VERSION ""

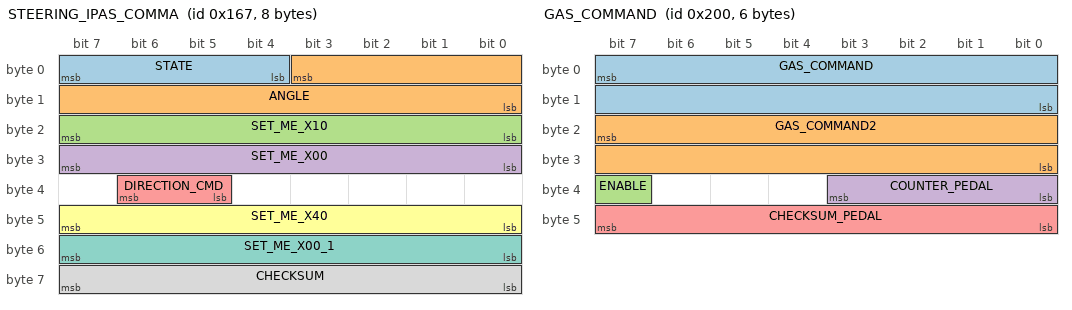
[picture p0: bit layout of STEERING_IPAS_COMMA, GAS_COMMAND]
BO_ 359 STEERING_IPAS_COMMA: 8 IPAS
 SG_ STATE : 7|4@0+ (1,0) [0|15] "" XXX
 SG_ ANGLE : 3|12@0- (1.5,0) [-510|510] "deg" XXX
 SG_ SET_ME_X10 : 23|8@0+ (1,0) [0|255] "" XXX
 SG_ SET_ME_X00 : 31|8@0+ (1,0) [0|255] "" XXX
 SG_ DIRECTION_CMD : 38|2@0+ (1,0) [0|3] "" XXX
 SG_ SET_ME_X40 : 47|8@0+ (1,0) [0|255] "" XXX
 SG_ SET_ME_X00_1 : 55|8@0+ (1,0) [0|255] "" XXX
 SG_ CHECKSUM : 63|8@0+ (1,0) [0|255] "" XXX

BO_ 512 GAS_COMMAND: 6 EON
 SG_ GAS_COMMAND : 7|16@0+ (0.159375,-75.555) [0|1] "" INTERCEPTOR
 SG_ GAS_COMMAND2 : 23|16@0+ (0.159375,-151.111) [0|1] "" INTERCEPTOR
 SG_ ENABLE : 39|1@0+ (1,0) [0|1] "" INTERCEPTOR
 SG_ COUNTER_PEDAL : 35|4@0+ (1,0) [0|15] "" INTERCEPTOR
 SG_ CHECKSUM_PEDAL : 47|8@0+ (1,0) [0|255] "" INTERCEPTOR

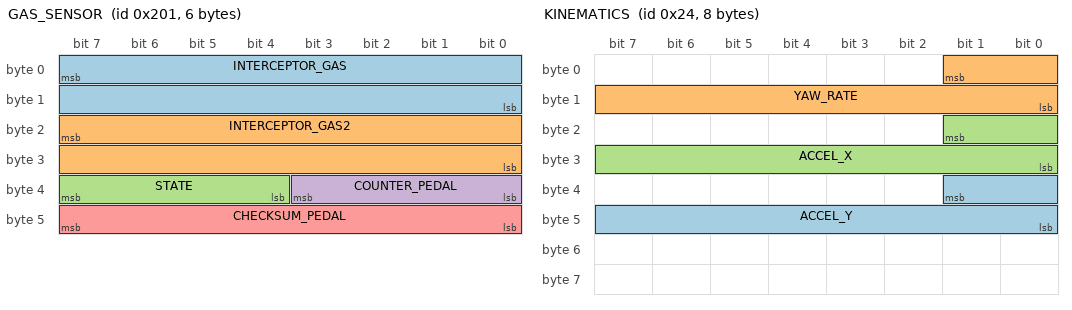
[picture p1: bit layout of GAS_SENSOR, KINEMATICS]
BO_ 513 GAS_SENSOR: 6 INTERCEPTOR
 SG_ INTERCEPTOR_GAS : 7|16@0+ (1,0) [0|1] "" EON
 SG_ INTERCEPTOR_GAS2 : 23|16@0+ (1,0) [0|1] "" EON
 SG_ STATE : 39|4@0+ (1,0) [0|15] "" EON
 SG_ COUNTER_PEDAL : 35|4@0+ (1,0) [0|15] "" EON
 SG_ CHECKSUM_PEDAL : 47|8@0+ (1,0) [0|255] "" EON

BO_ 35 SECONDARY_STEER_ANGLE: 8 XXX
 SG_ ZORRO_STEER : 7|24@0- (0.004901594652,0) [-500|500] "" XXX

BO_ 767 SDSU: 8 XXX
 SG_ FD_BUTTON : 7|1@0+ (1,0) [0|1] "" XXX

BO_ 36 KINEMATICS: 8 XXX
 SG_ ACCEL_Y : 33|10@0+ (0.03589,-18.375) [0|65535] "m/s^2" XXX
 SG_ YAW_RATE : 1|10@0+ (0.244,-125) [0|65535] "deg/s" XXX
 SG_ ACCEL_X : 17|10@0+ (0.03589,-18.375) [0|65535] "m/s^2" XXX

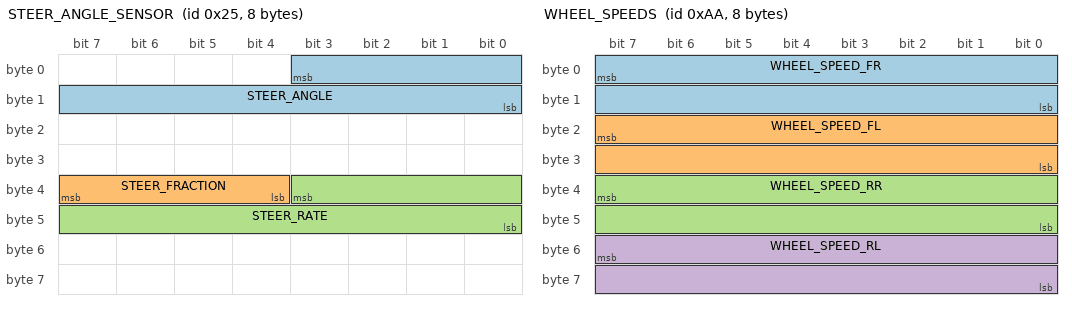
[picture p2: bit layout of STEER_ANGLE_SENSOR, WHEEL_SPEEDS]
BO_ 37 STEER_ANGLE_SENSOR: 8 XXX
 SG_ STEER_ANGLE : 3|12@0- (1.5,0) [-500|500] "deg" XXX
 SG_ STEER_FRACTION : 39|4@0- (0.1,0) [-0.7|0.7] "deg" XXX
 SG_ STEER_RATE : 35|12@0- (1,0) [-2000|2000] "deg/s" XXX

BO_ 166 BRAKE: 8 XXX
 SG_ BRAKE_AMOUNT : 7|8@0+ (1,0) [0|255] "" XXX
 SG_ BRAKE_PEDAL : 23|8@0+ (1,0) [0|255] "" XXX

BO_ 170 WHEEL_SPEEDS: 8 XXX
 SG_ WHEEL_SPEED_FR : 7|16@0+ (0.01,-67.67) [0|250] "km/h" XXX
 SG_ WHEEL_SPEED_FL : 23|16@0+ (0.01,-67.67) [0|250] "km/h" XXX
 SG_ WHEEL_SPEED_RR : 39|16@0+ (0.01,-67.67) [0|250] "km/h" XXX
 SG_ WHEEL_SPEED_RL : 55|16@0+ (0.01,-67.67) [0|250] "km/h" XXX

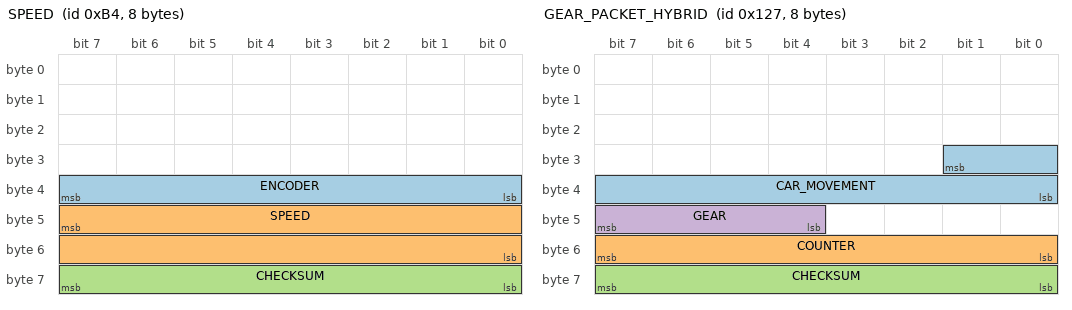
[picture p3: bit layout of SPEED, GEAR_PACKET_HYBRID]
BO_ 180 SPEED: 8 XXX
 SG_ ENCODER : 39|8@0+ (1,0) [0|255] "" XXX
 SG_ SPEED : 47|16@0+ (0.01,0) [0|250] "km/h" XXX
 SG_ CHECKSUM : 63|8@0+ (1,0) [0|255] "" XXX

BO_ 295 GEAR_PACKET_HYBRID: 8 XXX
 SG_ CAR_MOVEMENT : 25|10@0- (1,0) [0|255] "" XXX
 SG_ COUNTER : 55|8@0+ (1,0) [0|255] "" XXX
 SG_ CHECKSUM : 63|8@0+ (1,0) [0|255] "" XXX
 SG_ GEAR : 47|4@0+ (1,0) [0|15] "" XXX

BO_ 353 DSU_SPEED: 7 XXX
 SG_ FORWARD_SPEED : 15|16@0- (0.00390625,-30) [0|255] "km/h" XXX

BO_ 452 ENGINE_RPM: 8 CGW
 SG_ RPM : 7|16@0- (0.78125,0) [0|0] "rpm" SCS

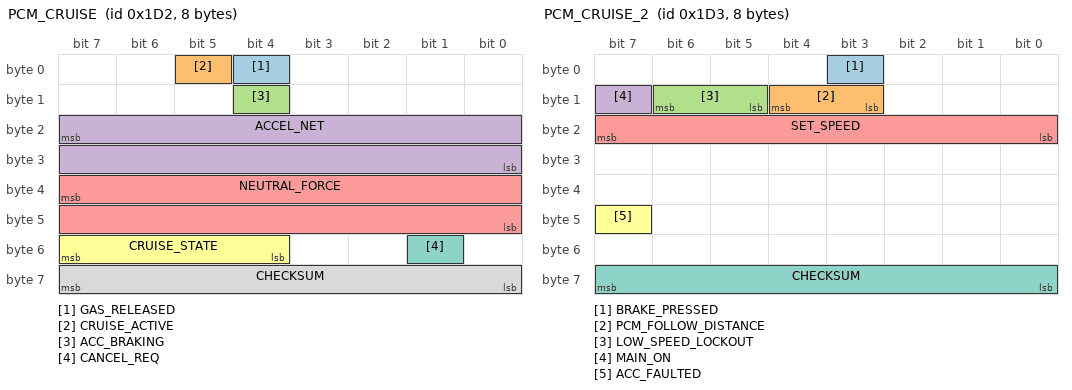
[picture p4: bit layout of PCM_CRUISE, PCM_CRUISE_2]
BO_ 466 PCM_CRUISE: 8 XXX
 SG_ GAS_RELEASED : 4|1@0+ (1,0) [0|1] "" XXX
 SG_ CRUISE_ACTIVE : 5|1@0+ (1,0) [0|1] "" XXX
 SG_ ACC_BRAKING : 12|1@0+ (1,0) [0|1] "" XXX
 SG_ ACCEL_NET : 23|16@0- (0.0009765625,0) [-20|20] "m/s^2" XXX
 SG_ NEUTRAL_FORCE : 39|16@0- (2,0) [-65536|65534] "N" XXX
 SG_ CRUISE_STATE : 55|4@0+ (1,0) [0|15] "" XXX
 SG_ CANCEL_REQ : 49|1@1+ (1,0) [0|1] "" XXX
 SG_ CHECKSUM : 63|8@0+ (1,0) [0|255] "" XXX

BO_ 467 PCM_CRUISE_2: 8 XXX
 SG_ BRAKE_PRESSED : 3|1@0+ (1,0) [0|1] "" XXX
 SG_ PCM_FOLLOW_DISTANCE : 12|2@0+ (1,0) [0|3] "" XXX
 SG_ LOW_SPEED_LOCKOUT : 14|2@0+ (1,0) [0|3] "" XXX
 SG_ MAIN_ON : 15|1@0+ (1,0) [0|1] "" XXX
 SG_ SET_SPEED : 23|8@0+ (1,0) [0|255] "km/h" XXX
 SG_ ACC_FAULTED : 47|1@0+ (1,0) [0|1] "" XXX
 SG_ CHECKSUM : 63|8@0+ (1,0) [0|255] "" XXX

BO_ 552 ACCELEROMETER: 8 XXX
 SG_ ACCEL_Z : 22|15@0- (1,0) [0|32767] "m/s^2" XXX
 SG_ ACCEL_X : 6|15@0- (0.001,0) [-20|20] "m/s^2" XXX

BO_ 560 BRAKE_2: 7 XXX
 SG_ BRAKE_PRESSED : 26|1@0+ (1,0) [0|1] "" XXX

BO_ 581 GAS_PEDAL_HYBRID: 8 XXX
 SG_ GAS_PEDAL : 23|8@0+ (0.005,0) [0|1] "" XXX

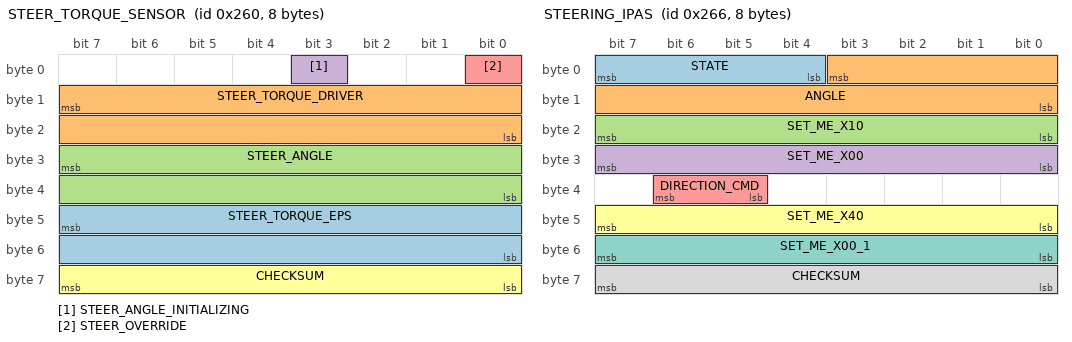
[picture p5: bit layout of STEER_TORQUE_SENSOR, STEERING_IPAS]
BO_ 608 STEER_TORQUE_SENSOR: 8 XXX
 SG_ STEER_TORQUE_EPS : 47|16@0- (1,0) [-32768|32767] "" XXX
 SG_ STEER_TORQUE_DRIVER : 15|16@0- (1,0) [-32768|32767] "" XXX
 SG_ STEER_ANGLE : 31|16@0- (0.0573,0) [-500|500] "" XXX
 SG_ STEER_ANGLE_INITIALIZING : 3|1@0+ (1,0) [0|1] "" XXX
 SG_ STEER_OVERRIDE : 0|1@0+ (1,0) [0|1] "" XXX
 SG_ CHECKSUM : 63|8@0+ (1,0) [0|255] "" XXX

BO_ 614 STEERING_IPAS: 8 IPAS
 SG_ STATE : 7|4@0+ (1,0) [0|15] "" XXX
 SG_ ANGLE : 3|12@0- (1.5,0) [-510|510] "deg" XXX
 SG_ SET_ME_X10 : 23|8@0+ (1,0) [0|255] "" XXX
 SG_ SET_ME_X00 : 31|8@0+ (1,0) [0|255] "" XXX
 SG_ DIRECTION_CMD : 38|2@0+ (1,0) [0|3] "" XXX
 SG_ SET_ME_X40 : 47|8@0+ (1,0) [0|255] "" XXX
 SG_ SET_ME_X00_1 : 55|8@0+ (1,0) [0|255] "" XXX
 SG_ CHECKSUM : 63|8@0+ (1,0) [0|255] "" XXX

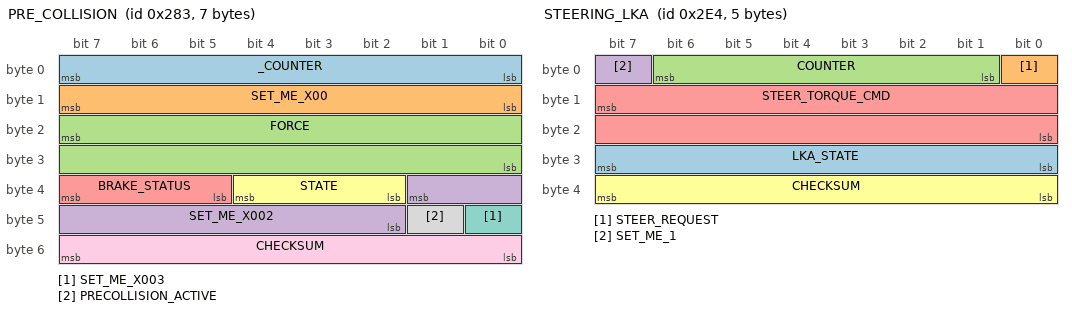
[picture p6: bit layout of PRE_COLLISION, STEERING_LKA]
BO_ 643 PRE_COLLISION: 7 DSU
 SG_ _COUNTER : 7|8@0+ (1,0) [0|255] "" XXX
 SG_ SET_ME_X00 : 15|8@0+ (1,0) [0|255] "" XXX
 SG_ FORCE : 23|16@0- (2,0) [0|255] "N" XXX
 SG_ SET_ME_X002 : 33|8@0+ (1,0) [0|3] "" XXX
 SG_ BRAKE_STATUS : 39|3@0+ (1,0) [0|255] "" XXX
 SG_ STATE : 36|3@0+ (1,0) [0|255] "" XXX
 SG_ SET_ME_X003 : 40|1@0+ (1,0) [0|1] "" XXX
 SG_ PRECOLLISION_ACTIVE : 41|1@0+ (1,0) [0|255] "" XXX
 SG_ CHECKSUM : 55|8@0+ (1,0) [0|255] "" XXX

BO_ 705 GAS_PEDAL: 8 XXX
 SG_ GAS_RELEASED : 3|1@0+ (1,0) [0|1] "" XXX
 SG_ GAS_PEDAL : 55|8@0+ (0.005,0) [0|1] "" XXX

BO_ 740 STEERING_LKA: 5 XXX
 SG_ LKA_STATE : 31|8@0+ (1,0) [0|255] "" XXX
 SG_ STEER_REQUEST : 0|1@0+ (1,0) [0|1] "" XXX
 SG_ COUNTER : 6|6@0+ (1,0) [0|63] "" XXX
 SG_ SET_ME_1 : 7|1@0+ (1,0) [0|1] "" XXX
 SG_ STEER_TORQUE_CMD : 15|16@0- (1,0) [0|65535] "" XXX
 SG_ CHECKSUM : 39|8@0+ (1,0) [0|255] "" XXX

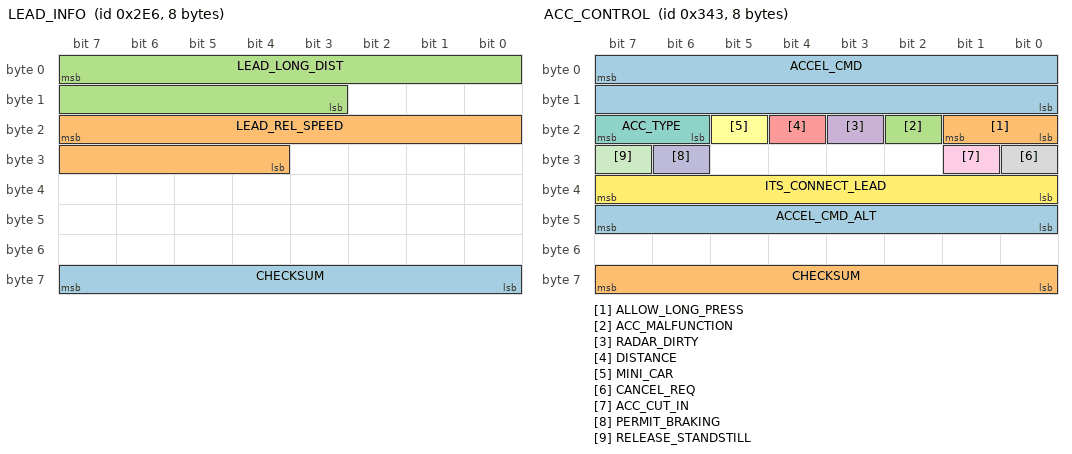
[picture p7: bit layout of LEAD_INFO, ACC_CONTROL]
BO_ 742 LEAD_INFO: 8 DSU
 SG_ CHECKSUM : 63|8@0+ (1,0) [0|255] "" HCU
 SG_ LEAD_REL_SPEED : 23|12@0- (0.025,0) [-100|100] "m/s" HCU
 SG_ LEAD_LONG_DIST : 7|13@0+ (0.05,0) [0|300] "m" HCU

BO_ 835 ACC_CONTROL: 8 DSU
 SG_ ACCEL_CMD : 7|16@0- (0.001,0) [-20|20] "m/s^2" HCU
 SG_ ALLOW_LONG_PRESS : 17|2@0+ (1,0) [0|2] "" XXX
 SG_ ACC_MALFUNCTION : 18|1@0+ (1,0) [0|0] "" XXX
 SG_ RADAR_DIRTY : 19|1@0+ (1,0) [0|1] "" XXX
 SG_ DISTANCE : 20|1@0+ (1,0) [0|1] "" XXX
 SG_ MINI_CAR : 21|1@0+ (1,0) [0|1] "" XXX
 SG_ ACC_TYPE : 23|2@0+ (1,0) [0|3] "" HCU
 SG_ CANCEL_REQ : 24|1@0+ (1,0) [0|1] "" HCU
 SG_ ACC_CUT_IN : 25|1@0+ (1,0) [0|1] "" XXX
 SG_ PERMIT_BRAKING : 30|1@0+ (1,0) [0|1] "" HCU
 SG_ RELEASE_STANDSTILL : 31|1@0+ (1,0) [0|1] "" HCU
 SG_ ITS_CONNECT_LEAD : 39|8@0+ (1,0) [0|1] "" Vector__XXX
 SG_ ACCEL_CMD_ALT : 47|8@0- (0.05,0) [0|0] "m/s^2" XXX
 SG_ CHECKSUM : 63|8@0+ (1,0) [0|255] "" XXX

BO_ 836 PRE_COLLISION_2: 8 DSU
 SG_ CHECKSUM : 63|8@0+ (1,0) [0|0] "" XXX

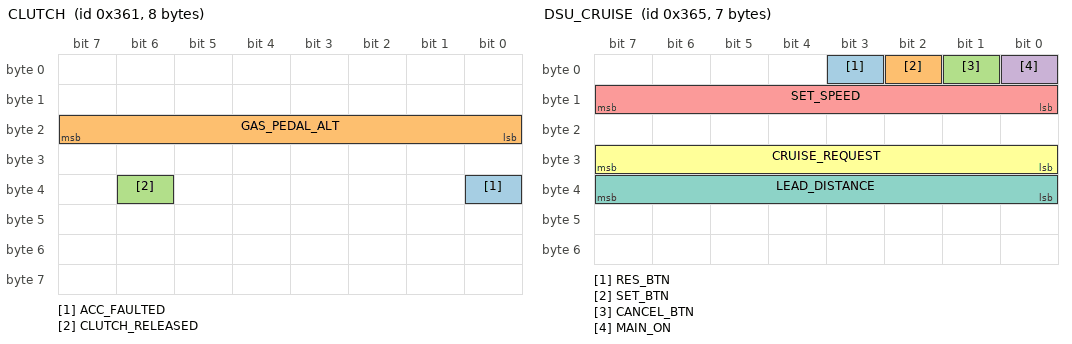
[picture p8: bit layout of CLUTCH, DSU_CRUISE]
BO_ 865 CLUTCH: 8 XXX
 SG_ ACC_FAULTED : 32|1@0+ (1,0) [0|1] "" XXX
 SG_ GAS_PEDAL_ALT : 23|8@0+ (0.005,0) [0|1] "" XXX
 SG_ CLUTCH_RELEASED : 38|1@0+ (1,0) [0|1] "" XXX

BO_ 869 DSU_CRUISE : 7 DSU
 SG_ RES_BTN : 3|1@0+ (1,0) [0|0] "" XXX
 SG_ SET_BTN : 2|1@0+ (1,0) [0|0] "" XXX
 SG_ CANCEL_BTN : 1|1@0+ (1,0) [0|0] "" XXX
 SG_ MAIN_ON : 0|1@0+ (1,0) [0|0] "" XXX
 SG_ SET_SPEED : 15|8@0+ (1,0) [0|0] "km/h" XXX
 SG_ CRUISE_REQUEST : 31|8@0+ (100,-12800) [0|0] "N" XXX
 SG_ LEAD_DISTANCE : 39|8@0+ (1,0) [0|0] "m" XXX

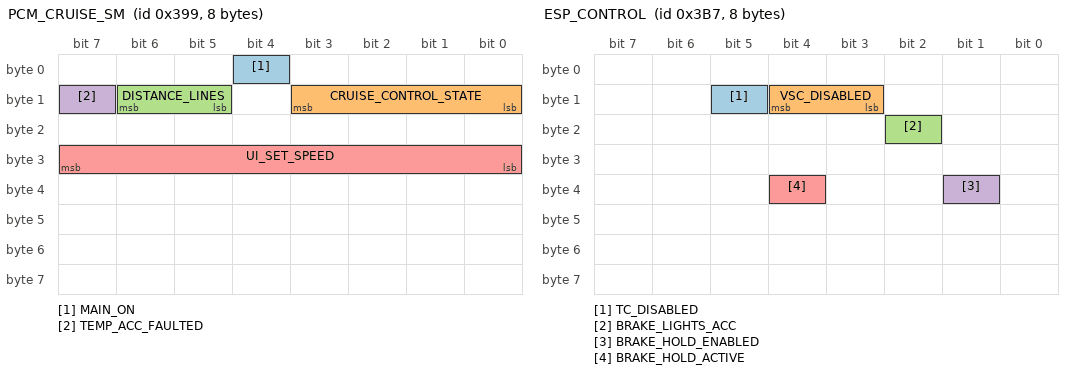
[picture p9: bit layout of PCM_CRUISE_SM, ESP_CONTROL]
BO_ 921 PCM_CRUISE_SM: 8 XXX
 SG_ MAIN_ON : 4|1@0+ (1,0) [0|1] "" XXX
 SG_ CRUISE_CONTROL_STATE : 11|4@0+ (1,0) [0|15] "" XXX
 SG_ DISTANCE_LINES : 14|2@0+ (1,0) [0|3] "" XXX
 SG_ TEMP_ACC_FAULTED : 15|1@0+ (1,0) [0|1] "" XXX
 SG_ UI_SET_SPEED : 31|8@0+ (1,0) [0|255] "" XXX

BO_ 951 ESP_CONTROL: 8 ESP
 SG_ TC_DISABLED : 13|1@0+ (1,0) [0|1] "" XXX
 SG_ VSC_DISABLED : 12|2@0+ (1,0) [0|1] "" XXX
 SG_ BRAKE_LIGHTS_ACC : 18|1@0+ (1,0) [0|1] "" XXX
 SG_ BRAKE_HOLD_ENABLED : 33|1@1+ (1,0) [0|1] "" XXX
 SG_ BRAKE_HOLD_ACTIVE : 36|1@0+ (1,0) [0|1] "" XXX

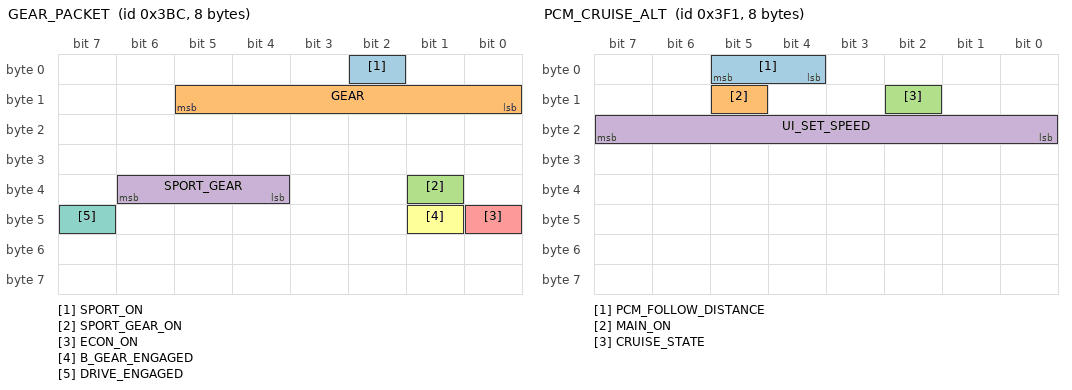
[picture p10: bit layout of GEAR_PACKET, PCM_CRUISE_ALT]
BO_ 956 GEAR_PACKET: 8 XXX
 SG_ SPORT_ON : 2|1@0+ (1,0) [0|1] "" XXX
 SG_ GEAR : 13|6@0+ (1,0) [0|63] "" XXX
 SG_ SPORT_GEAR_ON : 33|1@0+ (1,0) [0|1] "" XXX
 SG_ SPORT_GEAR : 38|3@0+ (1,0) [0|7] "" XXX
 SG_ ECON_ON : 40|1@0+ (1,0) [0|1] "" XXX
 SG_ B_GEAR_ENGAGED : 41|1@0+ (1,0) [0|1] "" XXX
 SG_ DRIVE_ENGAGED : 47|1@0+ (1,0) [0|1] "" XXX

BO_ 1005 REVERSE_CAMERA_STATE: 2 BGM
 SG_ REVERSE_CAMERA_GUIDELINES : 9|2@0+ (1,0) [1|3] "" XXX

BO_ 1009 PCM_CRUISE_ALT: 8 XXX
 SG_ PCM_FOLLOW_DISTANCE : 4|2@1+ (1,0) [0|3] "" XXX
 SG_ MAIN_ON : 13|1@0+ (1,0) [0|3] "" XXX
 SG_ CRUISE_STATE : 10|1@0+ (1,0) [0|1] "" XXX
 SG_ UI_SET_SPEED : 23|8@0+ (1,0) [0|255] "mph" XXX

BO_ 1020 SOLAR_SENSOR: 8 XXX
 SG_ LUX_SENSOR : 55|13@0+ (1,0) [0|0] "" XXX

BO_ 1041 PCS_HUD: 8 DSU
 SG_ PCS_INDICATOR : 7|2@0+ (1,0) [0|3] "" XXX
 SG_ FCW : 4|1@0+ (1,0) [0|1] "" XXX
 SG_ SET_ME_X20 : 15|8@0+ (1,0) [0|1] "" XXX
 SG_ PCS_DUST : 34|1@0+ (1,0) [0|0] "" XXX
 SG_ PCS_TEMP : 35|1@0+ (1,0) [0|0] "" XXX
 SG_ PCS_DUST2 : 41|1@0+ (1,0) [0|0] "" XXX
 SG_ PCS_TEMP2 : 42|1@0+ (1,0) [0|0] "" XXX
 SG_ SET_ME_X10 : 39|8@0+ (1,0) [0|1] "" XXX
 SG_ PCS_OFF : 40|1@0+ (1,0) [0|0] "" XXX
 SG_ FRD_ADJ : 53|3@0+ (1,0) [0|0] "" XXX
 SG_ PCS_SENSITIVITY : 55|8@0+ (1,0) [0|1] "" XXX

BO_ 1042 LKAS_HUD: 8 DSU
 SG_ BARRIERS : 1|2@0+ (1,0) [0|3] "" XXX
 SG_ RIGHT_LINE : 3|2@0+ (1,0) [0|3] "" XXX
 SG_ LEFT_LINE : 5|2@0+ (1,0) [0|3] "" XXX
 SG_ LKAS_STATUS : 7|2@0+ (1,0) [0|3] "" XXX
 SG_ LDA_ALERT : 9|2@0+ (1,0) [0|3] "" XXX
 SG_ LDW_EXIST : 10|1@0+ (1,0) [0|1] "" XXX
 SG_ TWO_BEEPS : 12|1@0+ (1,0) [0|1] "" XXX
 SG_ ADJUSTING_CAMERA : 13|1@0+ (1,0) [0|1] "" XXX
 SG_ LDA_UNAVAILABLE_QUIET : 14|1@0+ (1,0) [0|1] "" XXX
 SG_ LDA_MALFUNCTION : 15|1@0+ (1,0) [0|1] "" XXX
 SG_ LDA_UNAVAILABLE : 16|1@0+ (1,0) [0|1] "" XXX
 SG_ LDA_SENSITIVITY : 18|2@0+ (1,0) [0|3] "" XXX
 SG_ LDA_SA_TOGGLE : 20|2@0+ (1,0) [0|3] "" XXX
 SG_ LDA_MESSAGES : 23|3@0+ (1,0) [0|1] "" XXX
 SG_ LDA_ON_MESSAGE : 31|2@0+ (1,0) [0|3] "" XXX
 SG_ REPEATED_BEEPS : 32|1@0+ (1,0) [0|1] "" XXX
 SG_ LANE_SWAY_TOGGLE : 43|1@0+ (1,0) [0|1] "" XXX
 SG_ LANE_SWAY_SENSITIVITY : 45|2@0+ (1,0) [0|3] "" XXX
 SG_ TAKE_CONTROL : 46|1@0+ (1,0) [0|1] "" XXX
 SG_ LDA_FRONT_CAMERA_BLOCKED : 47|1@0+ (1,0) [0|1] "" XXX
 SG_ LANE_SWAY_BUZZER : 50|2@0+ (1,0) [0|0] "" XXX
 SG_ LANE_SWAY_FLD : 53|3@0+ (1,0) [0|7] "" XXX
 SG_ LANE_SWAY_WARNING : 55|2@0+ (1,0) [0|3] "" XXX
 SG_ SET_ME_X01 : 42|1@0+ (1,0) [0|1] "" XXX
 SG_ SET_ME_X02 : 63|8@0+ (1,0) [0|1] "" XXX

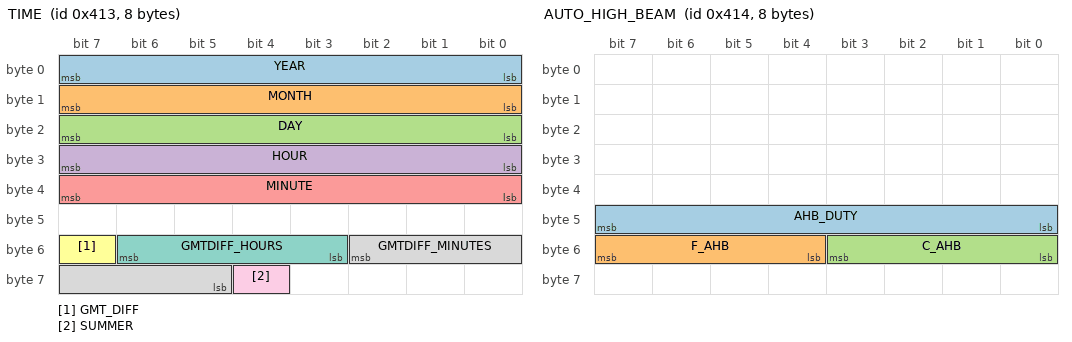
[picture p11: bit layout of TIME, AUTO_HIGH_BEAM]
BO_ 1043 TIME : 8 CGW
 SG_ YEAR : 7|8@0+ (1,0) [0|0] "year" XXX
 SG_ MONTH : 15|8@0+ (1,0) [0|0] "month" XXX
 SG_ DAY : 23|8@0+ (1,0) [0|0] "day" XXX
 SG_ HOUR : 31|8@0+ (1,0) [0|0] "hour" XXX
 SG_ MINUTE : 39|8@0+ (1,0) [0|0] "minute" XXX
 SG_ GMT_DIFF : 55|1@0+ (1,0) [0|0] "" XXX
 SG_ GMTDIFF_HOURS : 54|4@0+ (1,0) [0|0] "hours" XXX
 SG_ GMTDIFF_MINUTES : 50|6@0+ (1,0) [0|0] "minutes" XXX
 SG_ SUMMER : 60|1@0+ (1,0) [0|0] "" XXX

BO_ 1044 AUTO_HIGH_BEAM: 8 FCM
 SG_ AHB_DUTY : 47|8@0+ (0.5,0) [0|0] "%" Vector__XXX
 SG_ F_AHB : 55|4@0+ (1,0) [0|0] "" Vector__XXX
 SG_ C_AHB : 51|4@0+ (1,0) [0|0] "" Vector__XXX

BO_ 1083 AUTOPARK_STATUS: 8 IPAS
 SG_ STATE : 7|4@0+ (1,0) [0|15] "" XXX

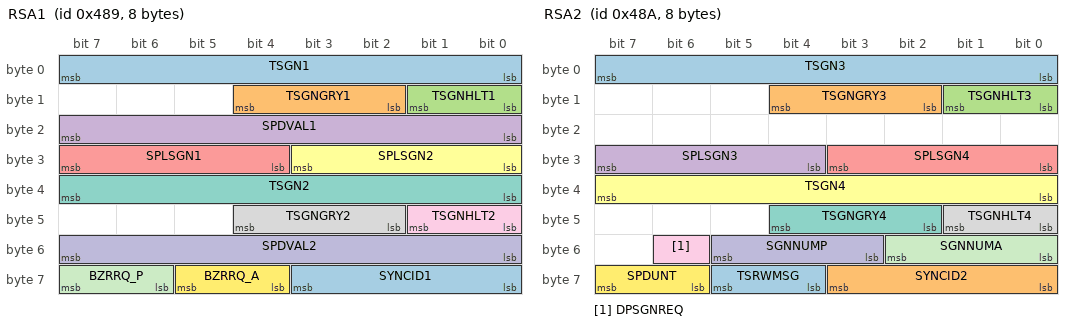
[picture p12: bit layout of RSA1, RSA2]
BO_ 1161 RSA1: 8 FCM
 SG_ TSGN1 : 7|8@0+ (1,0) [0|0] "" XXX
 SG_ TSGNGRY1 : 12|3@0+ (1,0) [0|0] "" XXX
 SG_ TSGNHLT1 : 9|2@0+ (1,0) [0|0] "" XXX
 SG_ SPDVAL1 : 23|8@0+ (1,0) [0|0] "km/h" XXX
 SG_ SPLSGN1 : 31|4@0+ (1,0) [0|0] "" XXX
 SG_ SPLSGN2 : 27|4@0+ (1,0) [0|0] "" XXX
 SG_ TSGN2 : 39|8@0+ (1,0) [0|0] "" XXX
 SG_ TSGNGRY2 : 44|3@0+ (1,0) [0|0] "" XXX
 SG_ TSGNHLT2 : 41|2@0+ (1,0) [0|0] "" XXX
 SG_ SPDVAL2 : 55|8@0+ (1,0) [0|0] "" XXX
 SG_ BZRRQ_P : 63|2@0+ (1,0) [0|0] "" XXX
 SG_ BZRRQ_A : 61|2@0+ (1,0) [0|0] "" XXX
 SG_ SYNCID1 : 59|4@0+ (1,0) [0|0] "" XXX

BO_ 1162 RSA2: 8 FCM
 SG_ TSGN3 : 7|8@0+ (1,0) [0|0] "" XXX
 SG_ TSGNGRY3 : 12|3@0+ (1,0) [0|0] "" XXX
 SG_ TSGNHLT3 : 9|2@0+ (1,0) [0|0] "" XXX
 SG_ SPLSGN3 : 31|4@0+ (1,0) [0|0] "" XXX
 SG_ SPLSGN4 : 27|4@0+ (1,0) [0|0] "" XXX
 SG_ TSGN4 : 39|8@0+ (1,0) [0|0] "" XXX
 SG_ TSGNGRY4 : 44|3@0+ (1,0) [0|0] "" XXX
 SG_ TSGNHLT4 : 41|2@0+ (1,0) [0|0] "" XXX
 SG_ DPSGNREQ : 54|1@0+ (1,0) [0|0] "" XXX
 SG_ SGNNUMP : 53|3@0+ (1,0) [0|0] "" XXX
 SG_ SGNNUMA : 50|3@0+ (1,0) [0|0] "" XXX
 SG_ SPDUNT : 63|2@0+ (1,0) [0|0] "" XXX
 SG_ TSRWMSG : 61|2@0+ (1,0) [0|0] "" XXX
 SG_ SYNCID2 : 59|4@0+ (1,0) [0|0] "" XXX

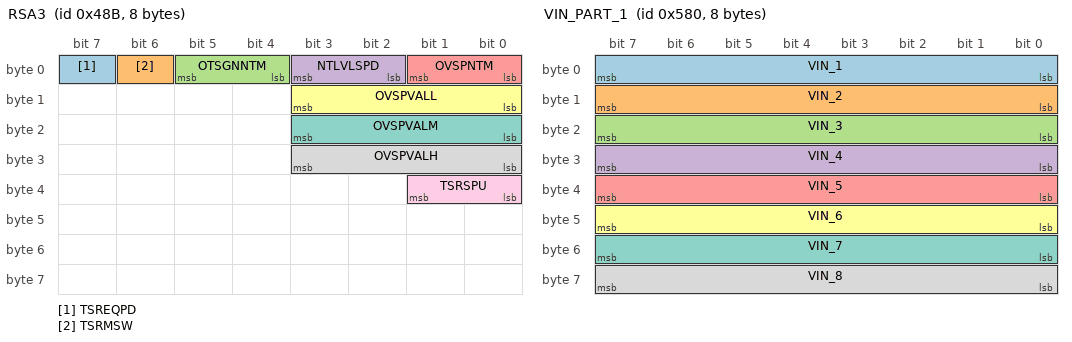
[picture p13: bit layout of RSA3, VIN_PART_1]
BO_ 1163 RSA3: 8 FCM
 SG_ TSREQPD : 7|1@0+ (1,0) [0|0] "" XXX
 SG_ TSRMSW : 6|1@0+ (1,0) [0|0] "" XXX
 SG_ OTSGNNTM : 5|2@0+ (1,0) [0|0] "" XXX
 SG_ NTLVLSPD : 3|2@0+ (1,0) [0|0] "" XXX
 SG_ OVSPNTM : 1|2@0+ (1,0) [0|0] "" XXX
 SG_ OVSPVALL : 11|4@0+ (1,-5) [0|0] "" XXX
 SG_ OVSPVALM : 19|4@0+ (1,-5) [0|0] "" XXX
 SG_ OVSPVALH : 27|4@0+ (1,-5) [0|0] "" XXX
 SG_ TSRSPU : 33|2@0+ (1,0) [0|0] "" XXX

BO_ 1408 VIN_PART_1: 8 CGW
 SG_ VIN_1 : 7|8@0+ (1,0) [0|0] "" XXX
 SG_ VIN_2 : 15|8@0+ (1,0) [0|0] "" XXX
 SG_ VIN_3 : 23|8@0+ (1,0) [0|0] "" XXX
 SG_ VIN_4 : 31|8@0+ (1,0) [0|0] "" XXX
 SG_ VIN_5 : 39|8@0+ (1,0) [0|0] "" XXX
 SG_ VIN_6 : 47|8@0+ (1,0) [0|0] "" XXX
 SG_ VIN_7 : 55|8@0+ (1,0) [0|0] "" XXX
 SG_ VIN_8 : 63|8@0+ (1,0) [0|0] "" XXX

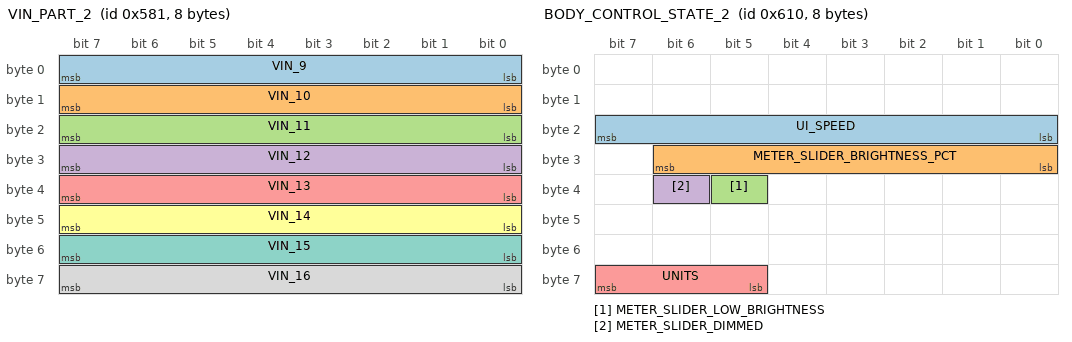
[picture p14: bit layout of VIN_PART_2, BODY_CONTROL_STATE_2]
BO_ 1409 VIN_PART_2: 8 CGW
 SG_ VIN_9 : 7|8@0+ (1,0) [0|0] "" XXX
 SG_ VIN_10 : 15|8@0+ (1,0) [0|0] "" XXX
 SG_ VIN_11 : 23|8@0+ (1,0) [0|0] "" XXX
 SG_ VIN_12 : 31|8@0+ (1,0) [0|0] "" XXX
 SG_ VIN_13 : 39|8@0+ (1,0) [0|0] "" XXX
 SG_ VIN_14 : 47|8@0+ (1,0) [0|0] "" XXX
 SG_ VIN_15 : 55|8@0+ (1,0) [0|0] "" XXX
 SG_ VIN_16 : 63|8@0+ (1,0) [0|0] "" XXX

BO_ 1410 VIN_PART_3: 8 CGW
 SG_ VIN_17 : 7|8@0+ (1,0) [0|0] "" XXX

BO_ 1552 BODY_CONTROL_STATE_2: 8 XXX
 SG_ UI_SPEED : 23|8@0+ (1,0) [0|255] "" XXX
 SG_ METER_SLIDER_BRIGHTNESS_PCT : 30|7@0+ (1,0) [12|100] "%" XXX
 SG_ METER_SLIDER_LOW_BRIGHTNESS : 37|1@0+ (1,0) [0|1] "" XXX
 SG_ METER_SLIDER_DIMMED : 38|1@0+ (1,0) [0|1] "" XXX
 SG_ UNITS : 63|3@0+ (1,0) [1|4] "" XXX

BO_ 1553 UI_SETTING: 8 XXX
 SG_ UNITS : 26|2@0+ (1,0) [0|3] "" XXX
 SG_ ODOMETER : 39|32@0+ (1,0) [0|1048575] "" XXX
BO_ 1556 BLINKERS_STATE: 8 XXX
 SG_ TURN_SIGNALS : 29|2@0+ (1,0) [0|3] "" XXX
 SG_ HAZARD_LIGHT : 27|1@0+ (1,0) [0|1] "" XXX

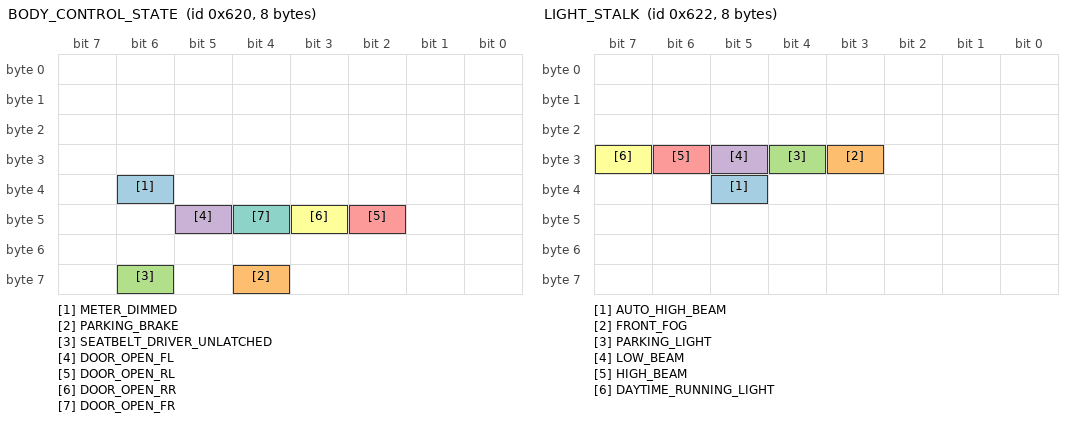
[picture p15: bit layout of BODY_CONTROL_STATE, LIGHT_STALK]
BO_ 1568 BODY_CONTROL_STATE: 8 XXX
 SG_ METER_DIMMED : 38|1@0+ (1,0) [0|1] "" XXX
 SG_ PARKING_BRAKE : 60|1@0+ (1,0) [0|1] "" XXX
 SG_ SEATBELT_DRIVER_UNLATCHED : 62|1@0+ (1,0) [0|1] "" XXX
 SG_ DOOR_OPEN_FL : 45|1@0+ (1,0) [0|1] "" XXX
 SG_ DOOR_OPEN_RL : 42|1@0+ (1,0) [0|1] "" XXX
 SG_ DOOR_OPEN_RR : 43|1@0+ (1,0) [0|1] "" XXX
 SG_ DOOR_OPEN_FR : 44|1@0+ (1,0) [0|1] "" XXX

BO_ 1570 LIGHT_STALK: 8 SCM
 SG_ AUTO_HIGH_BEAM : 37|1@0+ (1,0) [0|1] "" XXX
 SG_ FRONT_FOG : 27|1@0+ (1,0) [0|1] "" XXX
 SG_ PARKING_LIGHT : 28|1@0+ (1,0) [0|1] "" XXX
 SG_ LOW_BEAM : 29|1@0+ (1,0) [0|1] "" XXX
 SG_ HIGH_BEAM : 30|1@0+ (1,0) [0|1] "" XXX
 SG_ DAYTIME_RUNNING_LIGHT : 31|1@0+ (1,0) [0|1] "" XXX

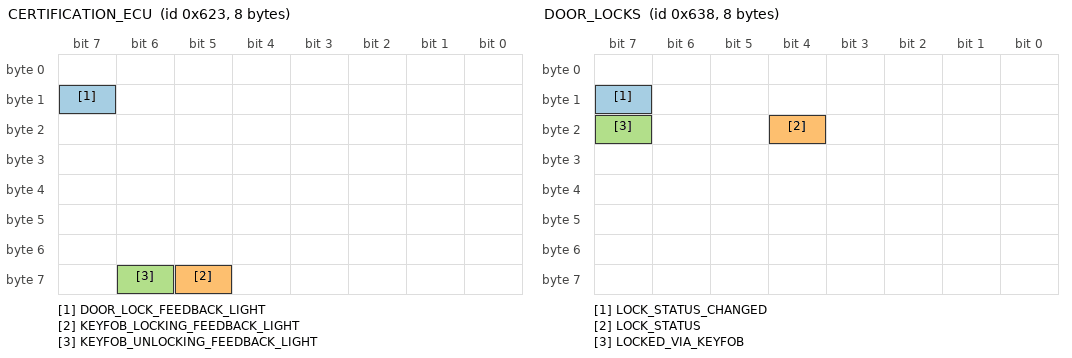
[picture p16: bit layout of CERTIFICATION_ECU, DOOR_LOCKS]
BO_ 1571 CERTIFICATION_ECU: 8 CGW
 SG_ DOOR_LOCK_FEEDBACK_LIGHT : 15|1@0+ (1,0) [0|0] "" XXX
 SG_ KEYFOB_LOCKING_FEEDBACK_LIGHT : 61|1@0+ (1,0) [0|0] "" XXX
 SG_ KEYFOB_UNLOCKING_FEEDBACK_LIGHT : 62|1@0+ (1,0) [0|0] "" XXX

BO_ 1592 DOOR_LOCKS: 8 XXX
 SG_ LOCK_STATUS_CHANGED : 15|1@0+ (1,0) [0|1] "" XXX
 SG_ LOCK_STATUS : 20|1@0+ (1,0) [0|1] "" XXX
 SG_ LOCKED_VIA_KEYFOB : 23|1@0+ (1,0) [0|1] "" XXX

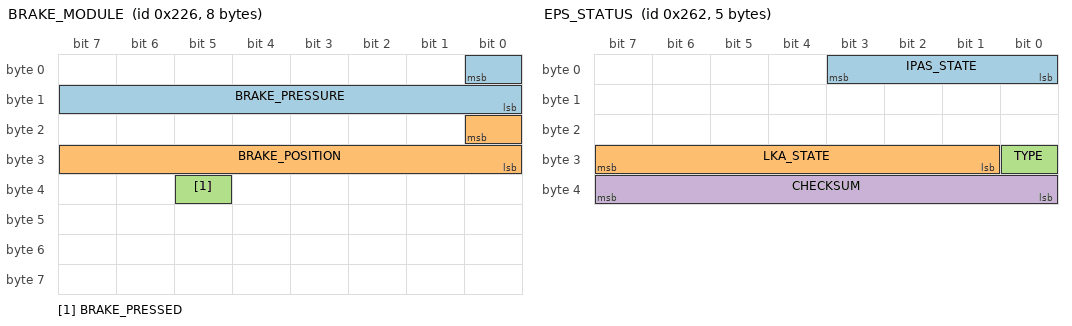
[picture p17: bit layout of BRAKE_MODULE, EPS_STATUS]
BO_ 550 BRAKE_MODULE: 8 XXX
 SG_ BRAKE_PRESSURE : 0|9@0+ (1,0) [0|511] "" XXX
 SG_ BRAKE_POSITION : 16|9@0+ (1,0) [0|511] "" XXX
 SG_ BRAKE_PRESSED : 37|1@0+ (1,0) [0|1] "" XXX

BO_ 610 EPS_STATUS: 5 EPS
 SG_ IPAS_STATE : 3|4@0+ (1,0) [0|15] "" XXX
 SG_ LKA_STATE : 31|7@0+ (1,0) [0|127] "" XXX
 SG_ TYPE : 24|1@0+ (1,0) [0|1] "" XXX
 SG_ CHECKSUM : 39|8@0+ (1,0) [0|255] "" XXX

BU_: XXX DSU HCU EPS IPAS

VAL_ 3 StW_Angl 16383 "SNA" ;
VAL_ 3 StW_AnglSens_Id 2 "MUST" 0 "PSBL" 1 "SELF" ;
VAL_ 3 StW_AnglSens_Stat 2 "ERR" 3 "ERR_INI" 1 "INI" 0 "OK" ;
VAL_ 3 StW_AnglSpd 16383 "SNA" ;
VAL_ 14 StW_AnglHP 16383 "SNA" ;
VAL_ 14 StW_AnglHP_Spd 16383 "SNA" ;
VAL_ 14 StW_AnglHP_Sens_Stat 3 "SNA" 2 "ERR" 1 "INI" 0 "OK" ;
VAL_ 14 StW_AnglHP_Sens_Id 3 "SNA" 2 "KOSTAL" 1 "DELPHI" 0 "TEST" ;
VAL_ 69 SpdCtrlLvr_Stat 32 "DN_1ST" 16 "UP_1ST" 8 "DN_2ND" 4 "UP_2ND" 2 "RWD" 1 "FWD" 0 "IDLE" ;
VAL_ 69 DTR_Dist_Rq 255 "SNA" 200 "ACC_DIST_7" 166 "ACC_DIST_6" 133 "ACC_DIST_5" 100 "ACC_DIST_4" 66 "ACC_DIST_3" 33 "ACC_DIST_2" 0 "ACC_DIST_1" ;
VAL_ 69 TurnIndLvr_Stat 3 "SNA" 2 "RIGHT" 1 "LEFT" 0 "IDLE" ;
VAL_ 69 HiBmLvr_Stat 3 "SNA" 2 "HIBM_FLSH_ON_PSD" 1 "HIBM_ON_PSD" 0 "IDLE" ;
VAL_ 69 WprWashSw_Psd 3 "SNA" 2 "WASH" 1 "TIPWIPE" 0 "NPSD" ;
VAL_ 69 WprWash_R_Sw_Posn_V2 3 "SNA" 2 "WASH" 1 "INTERVAL" 0 "OFF" ;
VAL_ 69 StW_Lvr_Stat 4 "STW_BACK" 3 "STW_FWD" 2 "STW_DOWN" 1 "STW_UP" 0 "NPSD" ;
VAL_ 69 StW_Cond_Psd 3 "SNA" 2 "DOWN" 1 "UP" 0 "NPSD" ;
VAL_ 69 HrnSw_Psd 3 "SNA" 2 "NDEF2" 1 "PSD" 0 "NPSD" ;
VAL_ 69 StW_Sw00_Psd 1 "PRESSED" 0 "NOT_PRESSED_SNA" ;
VAL_ 69 StW_Sw01_Psd 1 "PRESSED" 0 "NOT_PRESSED_SNA" ;
VAL_ 69 StW_Sw03_Psd 1 "PRESSED" 0 "NOT_PRESSED_SNA" ;
VAL_ 69 StW_Sw04_Psd 1 "PRESSED" 0 "NOT_PRESSED_SNA" ;
VAL_ 69 WprSw6Posn 7 "SNA" 6 "STAGE2" 5 "STAGE1" 4 "INTERVAL4" 3 "INTERVAL3" 2 "INTERVAL2" 1 "INTERVAL1" 0 "OFF" ;
VAL_ 257 GTW_epasControlType 0 "WITHOUT" 1 "WITH_ANGLE" 3 "WITH_BOTH" 2 "WITH_TORQUE" ;
VAL_ 109 StW_Sw_Stat3 7 "SNA" 6 "NDEF6" 5 "NDEF5" 4 "NDEF4" 3 "PLUS_MINUS" 2 "MINUS" 1 "PLUS" 0 "NPSD" ;
VAL_ 109 MsgTxmtId 3 "NDEF3" 2 "NDEF2" 1 "SCCM" 0 "EWM" ;
VAL_ 109 TSL_RND_Posn_StW 15 "SNA" 8 "D" 6 "INI" 4 "N_DOWN" 2 "N_UP" 1 "R" 0 "IDLE" ;
VAL_ 109 TSL_P_Psd_StW 3 "SNA" 2 "INI" 1 "PSD" 0 "IDLE" ;
VAL_ 257 GTW_epasEmergencyOn 1 "EMERGENCY_POWER" 0 "NONE" ;
VAL_ 257 GTW_epasLDWEnabled 1 "ALLOWED" 0 "INHIBITED" ;
VAL_ 257 GTW_epasPowerMode 0 "DRIVE_OFF" 1 "DRIVE_ON" 3 "LOAD_SHED" 2 "SHUTTING_DOWN" 15 "SNA" ;
VAL_ 257 GTW_epasTuneRequest 1 "DM_COMFORT" 3 "DM_SPORT" 2 "DM_STANDARD" 0 "FAIL_SAFE_DEFAULT" 4 "RWD_COMFORT" 6 "RWD_SPORT" 5 "RWD_STANDARD" 7 "SNA" ;
VAL_ 264 DI_torqueDriver -4096 "SNA" ;
VAL_ 264 DI_torqueMotor -4096 "SNA" ;
VAL_ 264 DI_soptState 7 "SOPT_TEST_SNA" 4 "SOPT_TEST_NOT_RUN" 3 "SOPT_TEST_PASSED" 2 "SOPT_TEST_FAILED" 1 "SOPT_TEST_IN_PROGRESS" 0 "SOPT_PRE_TEST" ;
VAL_ 264 DI_motorRPM -32768 "SNA" ;
VAL_ 264 DI_pedalPos 255 "SNA" ;
VAL_ 280 DI_torqueEstimate -2048 "SNA" ;
VAL_ 280 DI_gear 7 "DI_GEAR_SNA" 4 "DI_GEAR_D" 3 "DI_GEAR_N" 2 "DI_GEAR_R" 1 "DI_GEAR_P" 0 "DI_GEAR_INVALID" ;
VAL_ 280 DI_brakePedal 1 "Applied" 0 "Not_applied" ;
VAL_ 280 DI_vehicleSpeed 4095 "SNA" ;
VAL_ 280 DI_gearRequest 7 "DI_GEAR_SNA" 4 "DI_GEAR_D" 3 "DI_GEAR_N" 2 "DI_GEAR_R" 1 "DI_GEAR_P" 0 "DI_GEAR_INVALID" ;
VAL_ 280 DI_torqueInterfaceFailure 1 "TORQUE_INTERFACE_FAILED" 0 "TORQUE_INTERFACE_NORMAL" ;
VAL_ 280 DI_brakePedalState 3 "SNA" 2 "INVALID" 1 "ON" 0 "OFF" ;
VAL_ 280 DI_epbParkRequest 1 "Park_requested" 0 "No_request" ;
VAL_ 280 DI_epbInterfaceReady 1 "EPB_INTERFACE_READY" 0 "EPB_INTERFACE_NOT_READY" ;
VAL_ 309 ESP_absBrakeEvent 1 "ACTIVE" 0 "NOT_ACTIVE" ;
VAL_ 309 ESP_brakeDiscWipingActive 1 "ACTIVE" 0 "INACTIVE" ;
VAL_ 309 ESP_brakeLamp 0 "OFF" 1 "ON" ;
VAL_ 309 ESP_espFaultLamp 0 "OFF" 1 "ON" ;
VAL_ 309 ESP_espLampFlash 1 "FLASH" 0 "OFF" ;
VAL_ 309 ESP_hillStartAssistActive 1 "ACTIVE" 0 "INACTIVE" 2 "NOT_AVAILABLE" 3 "SNA" ;
VAL_ 309 ESP_absFaultLamp 0 "OFF" 1 "ON" ;
VAL_ 309 ESP_espOffLamp 0 "OFF" 1 "ON" ;
VAL_ 309 ESP_stabilityControlSts 2 "ENGAGED" 3 "FAULTED" 5 "INIT" 4 "NOT_CONFIGURED" 0 "OFF" 1 "ON" ;
VAL_ 309 ESP_tcLampFlash 1 "FLASH" 0 "OFF" ;
VAL_ 568 UI_mapSpeedLimit 31 "SNA" 30 "UNLIMITED" 29 "LESS_OR_EQ_160" 28 "LESS_OR_EQ_150" 27 "LESS_OR_EQ_140" 26 "LESS_OR_EQ_130" 25 "LESS_OR_EQ_120" 24 "LESS_OR_EQ_115" 23 "LESS_OR_EQ_110" 22 "LESS_OR_EQ_105" 21 "LESS_OR_EQ_100" 20 "LESS_OR_EQ_95" 19 "LESS_OR_EQ_90" 18 "LESS_OR_EQ_85" 17 "LESS_OR_EQ_80" 16 "LESS_OR_EQ_75" 15 "LESS_OR_EQ_70" 14 "LESS_OR_EQ_65" 13 "LESS_OR_EQ_60" 12 "LESS_OR_EQ_55" 11 "LESS_OR_EQ_50" 10 "LESS_OR_EQ_45" 9 "LESS_OR_EQ_40" 8 "LESS_OR_EQ_35" 7 "LESS_OR_EQ_30" 6 "LESS_OR_EQ_25" 5 "LESS_OR_EQ_20" 4 "LESS_OR_EQ_15" 3 "LESS_OR_EQ_10" 2 "LESS_OR_EQ_7" 1 "LESS_OR_EQ_5" 0 "UNKNOWN" ;
VAL_ 569 DAS_leftLineUsage 3 "BLACKLISTED" 2 "FUSED" 1 "AVAILABLE" 0 "REJECTED_UNAVAILABLE" ;
VAL_ 569 DAS_rightLineUsage 3 "BLACKLISTED" 2 "FUSED" 1 "AVAILABLE" 0 "REJECTED_UNAVAILABLE" ;
VAL_ 569 DAS_leftFork 3 "LEFT_FORK_UNAVAILABLE" 2 "LEFT_FORK_SELECTED" 1 "LEFT_FORK_AVAILABLE" 0 "LEFT_FORK_NONE" ;
VAL_ 569 DAS_rightFork 3 "RIGHT_FORK_UNAVAILABLE" 2 "RIGHT_FORK_SELECTED" 1 "RIGHT_FORK_AVAILABLE" 0 "RIGHT_FORK_NONE" ;
VAL_ 521 DAS_locMode 3 "DAS_LOC_DRIVERLESS" 2 "DAS_LOC_RESTRICTED" 1 "DAS_LOC_NORMAL" 0 "DAS_LOC_OFF" ;
VAL_ 521 DAS_locState 7 "DAS_LOC_FAULT_SNA" 6 "DAS_LOC_AEB_ACTIVE" 2 "DAS_LOC_CANCEL_SILENT" 1 "DAS_LOC_CANCEL_GENERIC" 0 "DAS_LOC_HEALTHY" ;
VAL_ 521 DAS_locRequest 4 "DAS_RQ_PARK" 3 "DAS_RQ_HOLD" 2 "DAS_RQ_BACKWARD" 1 "DAS_RQ_FORWARD" 0 "DAS_RQ_IDLE" ;
VAL_ 521 DAS_locJerkMin 255 "SNA" ;
VAL_ 521 DAS_locJerkMax 255 "SNA" ;
VAL_ 521 DAS_locSpeed 2047 "SNA" ;
VAL_ 521 DAS_locAccelMin 511 "SNA" ;
VAL_ 521 DAS_locAccelMax 511 "SNA" ;
VAL_ 522 driverBrakeStatus 2 "APPLIED" 1 "NOT_APPLIED" ;
VAL_ 760 UI_mapSpeedLimitUnits 1 "KPH" 0 "MPH" ;
VAL_ 760 UI_userSpeedOffsetUnits 1 "KPH" 0 "MPH" ;
VAL_ 643 AirTemp_Insd 255 "SNA" ;
VAL_ 643 AirTemp_Outsd 254 "INIT" 255 "SNA" ;
VAL_ 643 Bckl_Sw_RL_Stat_SAM_R 2 "FLT" 1 "NOT" 0 "OK" 3 "SNA" ;
VAL_ 643 Bckl_Sw_RM_Stat_SAM_R 2 "FLT" 1 "NOT" 0 "OK" 3 "SNA" ;
VAL_ 643 Bckl_Sw_RR_Stat_SAM_R 2 "FLT" 1 "NOT" 0 "OK" 3 "SNA" ;
VAL_ 643 DL_RLtch_Stat 1 "CLS" 0 "NDEF0" 2 "OPN" 3 "SNA" ;
VAL_ 643 DrRLtch_FL_Stat 1 "CLS" 0 "NDEF0" 2 "OPN" 3 "SNA" ;
VAL_ 643 DrRLtch_FR_Stat 1 "CLS" 0 "NDEF0" 2 "OPN" 3 "SNA" ;
VAL_ 643 DrRLtch_RL_Stat 1 "CLS" 0 "NDEF0" 2 "OPN" 3 "SNA" ;
VAL_ 643 DrRLtch_RR_Stat 1 "CLS" 0 "NDEF0" 2 "OPN" 3 "SNA" ;
VAL_ 643 EngHd_Stat 1 "CLS" 0 "NDEF0" 2 "OPN" 3 "SNA" ;
VAL_ 643 LgtSens_Night 0 "DAY" 1 "NIGHT" ;
VAL_ 643 MPkBrk_Stat 1 "ENGG" 0 "RELS" ;
VAL_ 643 RevGr_Engg 0 "DISENGG" 1 "ENGG" 2 "NDEF2" 3 "SNA" ;
VAL_ 643 StW_Cond_Stat 3 "BLINK" 1 "NDEF1" 0 "OFF" 2 "ON" ;
VAL_ 643 Trlr_Stat 2 "NDEF2" 0 "NONE" 1 "OK" 3 "SNA" ;
VAL_ 697 DAS_setSpeed 4095 "SNA" ;
VAL_ 697 DAS_accState 15 "FAULT_SNA" 13 "ACC_CANCEL_GENERIC_SILENT" 11 "APC_SELFPARK_START" 10 "APC_UNPARK_COMPLETE" 9 "APC_PAUSE" 8 "APC_ABORT" 7 "APC_COMPLETE" 6 "APC_FORWARD" 5 "APC_BACKWARD" 4 "ACC_ON" 3 "ACC_HOLD" 0 "ACC_CANCEL_GENERIC" ;
VAL_ 697 DAS_aebEvent 3 "AEB_SNA" 2 "AEB_FAULT" 1 "AEB_ACTIVE" 0 "AEB_NOT_ACTIVE" ;
VAL_ 697 DAS_jerkMin 511 "SNA" ;
VAL_ 697 DAS_jerkMax 255 "SNA" ;
VAL_ 697 DAS_accelMin 511 "SNA" ;
VAL_ 697 DAS_accelMax 511 "SNA" ;
VAL_ 792 BOOT_STATE 2 "Init" 3 "SNA" 0 "closed" 1 "open" ;
VAL_ 792 CERRD 1 "CAN error detect" 0 "no Can error detected" ;
VAL_ 792 DAY 1 "Init" 0 "SNA" ;
VAL_ 792 DOOR_STATE_FL 2 "Init" 3 "SNA" 0 "closed" 1 "open" ;
VAL_ 792 DOOR_STATE_FR 2 "Init" 3 "SNA" 0 "closed" 1 "open" ;
VAL_ 792 DOOR_STATE_FrontTrunk 2 "Init" 3 "SNA" 0 "closed" 1 "open" ;
VAL_ 792 DOOR_STATE_RL 2 "Init" 3 "SNA" 0 "closed" 1 "open" ;
VAL_ 792 DOOR_STATE_RR 2 "Init" 3 "SNA" 0 "closed" 1 "open" ;
VAL_ 792 GTW_updateInProgress 1 "IN_PROGRESS" 2 "IN_PROGRESS_NOT_USED" 3 "IN_PROGRESS_SNA" 0 "NOT_IN_PROGRESS" ;
VAL_ 792 Hour 30 "Init" 31 "SNA" ;
VAL_ 792 MCU_factoryMode 1 "FACTORY_MODE" 0 "NORMAL_MODE" ;
VAL_ 792 MCU_transportModeOn 0 "NORMAL_MODE" ;
VAL_ 792 MINUTE 62 "Init" 63 "SNA" ;
VAL_ 792 MONTH 1 "Init" 15 "SNA" ;
VAL_ 792 SECOND 62 "Init" 63 "SNA" ;
VAL_ 792 YEAR 126 "Init" 127 "SNA" ;
VAL_ 872 DI_aebState 2 "ENABLED" 4 "FAULT" 7 "SNA" 1 "STANDBY" 3 "STANDSTILL" 0 "UNAVAILABLE" ;
VAL_ 872 DI_analogSpeed 4095 "SNA" ;
VAL_ 872 DI_cruiseState 2 "ENABLED" 5 "FAULT" 0 "OFF" 4 "OVERRIDE" 7 "PRE_CANCEL" 6 "PRE_FAULT" 1 "STANDBY" 3 "STANDSTILL" ;
VAL_ 872 DI_digitalSpeed 255 "SNA" ;
VAL_ 872 DI_immobilizerState 2 "AUTHENTICATING" 3 "DISARMED" 6 "FAULT" 4 "IDLE" 0 "INIT_SNA" 1 "REQUEST" 5 "RESET" ;
VAL_ 872 DI_speedUnits 1 "KPH" 0 "MPH" ;
VAL_ 872 DI_state 3 "ABORT" 4 "ENABLE" 2 "FAULT" 1 "STANDBY" 0 "UNAVAILABLE" ;
VAL_ 872 DI_systemState 3 "ABORT" 4 "ENABLE" 2 "FAULT" 1 "STANDBY" 0 "UNAVAILABLE" ;
VAL_ 872 DI_vehicleHoldState 2 "BLEND_IN" 4 "BLEND_OUT" 6 "FAULT" 7 "INIT" 5 "PARK" 1 "STANDBY" 3 "STANDSTILL" 0 "UNAVAILABLE" ;
VAL_ 880 EPAS_currentTuneMode 1 "DM_COMFORT" 3 "DM_SPORT" 2 "DM_STANDARD" 0 "FAIL_SAFE_DEFAULT" 4 "RWD_COMFORT" 6 "RWD_SPORT" 5 "RWD_STANDARD" 7 "UNAVAILABLE" ;
VAL_ 880 EPAS_eacErrorCode 14 "EAC_ERROR_EPB_INHIBIT" 3 "EAC_ERROR_HANDS_ON" 7 "EAC_ERROR_HIGH_ANGLE_RATE_REQ" 9 "EAC_ERROR_HIGH_ANGLE_RATE_SAFETY" 6 "EAC_ERROR_HIGH_ANGLE_REQ" 8 "EAC_ERROR_HIGH_ANGLE_SAFETY" 10 "EAC_ERROR_HIGH_MMOT_SAFETY" 11 "EAC_ERROR_HIGH_TORSION_SAFETY" 0 "EAC_ERROR_IDLE" 12 "EAC_ERROR_LOW_ASSIST" 2 "EAC_ERROR_MAX_SPEED" 1 "EAC_ERROR_MIN_SPEED" 13 "EAC_ERROR_PINION_VEL_DIFF" 4 "EAC_ERROR_TMP_FAULT" 5 "EAR_ERROR_MAX_STEER_DELTA" 15 "SNA" ;
VAL_ 880 EPAS_eacStatus 2 "EAC_ACTIVE" 1 "EAC_AVAILABLE" 3 "EAC_FAULT" 0 "EAC_INHIBITED" 4 "SNA" ;
VAL_ 880 EPAS_handsOnLevel 0 "0" 1 "1" 2 "2" 3 "3" ;
VAL_ 880 EPAS_steeringFault 1 "FAULT" 0 "NO_FAULT" ;
VAL_ 880 EPAS_steeringRackForce 1022 "NOT_IN_SPEC" 1023 "SNA" ;
VAL_ 880 EPAS_steeringReduced 0 "NORMAL_ASSIST" 1 "REDUCED_ASSIST" ;
VAL_ 880 EPAS_torsionBarTorque 0 "SEE_SPECIFICATION" 4095 "SNA" 4094 "UNDEFINABLE_DATA" ;
VAL_ 904 MCU_clusterReadyForDrive 0 "NO_SNA" 1 "YES" ;
VAL_ 905 DAS_accSpeedLimit 1023 "SNA" 0 "NONE" ;
VAL_ 905 DAS_pmmObstacleSeverity 7 "PMM_SNA" 6 "PMM_ACCEL_LIMIT" 5 "PMM_CRASH_FRONT" 4 "PMM_CRASH_REAR" 3 "PMM_BRAKE_REQUEST" 2 "PMM_IMMINENT_FRONT" 1 "PMM_IMMINENT_REAR" 0 "PMM_NONE" ;
VAL_ 905 DAS_pmmLoggingRequest 1 "TRUE" 0 "FALSE" ;
VAL_ 905 DAS_activationFailureStatus 2 "LC_ACTIVATION_FAILED_2" 1 "LC_ACTIVATION_FAILED_1" 0 "LC_ACTIVATION_IDLE" ;
VAL_ 905 DAS_pmmUltrasonicsFaultReason 4 "PMM_ULTRASONICS_INVALID_MIA" 3 "PMM_ULTRASONICS_BLOCKED_BOTH" 2 "PMM_ULTRASONICS_BLOCKED_REAR" 1 "PMM_ULTRASONICS_BLOCKED_FRONT" 0 "PMM_ULTRASONICS_NO_FAULT" ;
VAL_ 905 DAS_pmmRadarFaultReason 2 "PMM_RADAR_INVALID_MIA" 1 "PMM_RADAR_BLOCKED_FRONT" 0 "PMM_RADAR_NO_FAULT" ;
VAL_ 905 DAS_pmmSysFaultReason 7 "PMM_FAULT_BRAKE_PEDAL_INHIBIT" 6 "PMM_FAULT_ROAD_TYPE" 5 "PMM_FAULT_DISABLED_BY_USER" 4 "PMM_FAULT_STEERING_ANGLE_RATE" 3 "PMM_FAULT_DI_FAULT" 2 "PMM_FAULT_SPEED" 1 "PMM_FAULT_DAS_DISABLED" 0 "PMM_FAULT_NONE" ;
VAL_ 905 DAS_pmmCameraFaultReason 2 "PMM_CAMERA_INVALID_MIA" 1 "PMM_CAMERA_BLOCKED_FRONT" 0 "PMM_CAMERA_NO_FAULT" ;
VAL_ 905 DAS_ACC_report 24 "ACC_REPORT_BEHAVIOR_REPORT" 23 "ACC_REPORT_CAMERA_ONLY" 22 "ACC_REPORT_RADAR_OBJ_FIVE" 21 "ACC_REPORT_CIPV_CUTTING_OUT" 20 "ACC_REPORT_MCVLR_IN_PATH" 19 "ACC_REPORT_MCVLR_DPP" 18 "ACC_REPORT_FLEET_SPEEDS" 17 "ACC_REPORT_TARGET_MCP" 16 "ACC_REPORT_RADAR_OBJ_TWO" 15 "ACC_REPORT_RADAR_OBJ_ONE" 14 "ACC_REPORT_LC_EXTERNAL_STATE_ACTIVE_RESTRICTED" 13 "ACC_REPORT_LC_EXTERNAL_STATE_ABORTED" 12 "ACC_REPORT_LC_EXTERNAL_STATE_ABORTING" 11 "ACC_REPORT_LC_HANDS_ON_REQD_STRUCK_OUT" 10 "ACC_REPORT_CSA" 9 "ACC_REPORT_TARGET_TYPE_FAULT" 8 "ACC_REPORT_TARGET_TYPE_IPSO" 7 "ACC_REPORT_TARGET_TYPE_TRAFFIC_LIGHT" 6 "ACC_REPORT_TARGET_TYPE_STOP_SIGN" 5 "ACC_REPORT_TARGET_CUTIN" 4 "ACC_REPORT_TARGET_MCVR" 3 "ACC_REPORT_TARGET_MCVL" 2 "ACC_REPORT_TARGET_IN_FRONT_OF_CIPV" 1 "ACC_REPORT_TARGET_CIPV" 0 "ACC_REPORT_TARGET_NONE" ;
VAL_ 905 DAS_lssState 7 "LSS_STATE_OFF" 6 "LSS_STATE_ABORT" 5 "LSS_STATE_BLINDSPOT" 4 "LSS_STATE_MONITOR" 3 "LSS_STATE_ELK" 2 "LSS_STATE_LKA" 1 "LSS_STATE_LDW" 0 "LSS_STATE_FAULT" ;
VAL_ 905 DAS_radarTelemetry 2 "RADAR_TELEMETRY_URGENT" 1 "RADAR_TELEMETRY_NORMAL" 0 "RADAR_TELEMETRY_IDLE" ;
VAL_ 905 DAS_robState 3 "ROB_STATE_MAPLESS" 2 "ROB_STATE_ACTIVE" 1 "ROB_STATE_MEASURE" 0 "ROB_STATE_INHIBITED" ;
VAL_ 905 DAS_driverInteractionLevel 2 "CONTINUED_DRIVER_NOT_INTERACTING" 1 "DRIVER_NOT_INTERACTING" 0 "DRIVER_INTERACTING" ;
VAL_ 905 DAS_ppOffsetDesiredRamp 128 "PP_NO_OFFSET" ;
VAL_ 905 DAS_longCollisionWarning 15 "FCM_LONG_COLLISION_WARNING_SNA" 12 "FCM_LONG_COLLISION_WARNING_VEHICLE_CIPV2" 11 "FCM_LONG_COLLISION_WARNING_VEHICLE_MCVR2" 10 "FCM_LONG_COLLISION_WARNING_VEHICLE_MCVR" 9 "FCM_LONG_COLLISION_WARNING_VEHICLE_MCVL2" 8 "FCM_LONG_COLLISION_WARNING_VEHICLE_MCVL" 7 "FCM_LONG_COLLISION_WARNING_VEHICLE_CUTIN" 6 "FCM_LONG_COLLISION_WARNING_VEHICLE_CIPV" 5 "FCM_LONG_COLLISION_WARNING_TFL_STOPLINE" 4 "FCM_LONG_COLLISION_WARNING_STOPSIGN_STOPLINE" 3 "FCM_LONG_COLLISION_WARNING_IPSO" 2 "FCM_LONG_COLLISION_WARNING_PEDESTRIAN" 1 "FCM_LONG_COLLISION_WARNING_VEHICLE_UNKNOWN" 0 "FCM_LONG_COLLISION_WARNING_NONE" ;
VAL_ 921 autopilotStatus 5 "ACTIVE_NAVIGATE_ON_AUTOPILOT" 4 "ACTIVE_2" 3 "ACTIVE_1" 2 "AVAILABLE" 1 "UNAVAILABLE" 0 "DISABLED" ;
VAL_ 921 DAS_blindSpotRearLeft 3 "SNA" 2 "WARNING_LEVEL_2" 1 "WARNING_LEVEL_1" 0 "NO_WARNING" ;
VAL_ 921 DAS_blindSpotRearRight 3 "SNA" 2 "WARNING_LEVEL_2" 1 "WARNING_LEVEL_1" 0 "NO_WARNING" ;
VAL_ 921 DAS_fusedSpeedLimit 31 "NONE" 0 "UNKNOWN_SNA" ;
VAL_ 921 DAS_suppressSpeedWarning 1 "Suppress_Speed_Warning" 0 "Do_Not_Suppress" ;
VAL_ 921 DAS_visionOnlySpeedLimit 31 "NONE" 0 "UNKNOWN_SNA" ;
VAL_ 921 DAS_heaterState 1 "HEATER_ON" 0 "HEATER_OFF_SNA" ;
VAL_ 921 DAS_forwardCollisionWarning 3 "SNA" 1 "FORWARD_COLLISION_WARNING" 0 "NONE" ;
VAL_ 921 DAS_autoparkReady 1 "AUTOPARK_READY" 0 "AUTOPARK_UNAVAILABLE" ;
VAL_ 921 DAS_sideCollisionAvoid 3 "SNA" 2 "AVOID_RIGHT" 1 "AVOID_LEFT" 0 "NONE" ;
VAL_ 921 DAS_sideCollisionWarning 3 "WARN_LEFT_RIGHT" 2 "WARN_RIGHT" 1 "WARN_LEFT" 0 "NONE" ;
VAL_ 921 DAS_sideCollisionInhibit 1 "INHIBIT" 0 "NO_INHIBIT" ;
VAL_ 921 DAS_csaState 3 "CSA_EXTERNAL_STATE_HOLD" 2 "CSA_EXTERNAL_STATE_ENABLE" 1 "CSA_EXTERNAL_STATE_AVAILABLE" 0 "CSA_EXTERNAL_STATE_UNAVAILABLE" ;
VAL_ 921 DAS_laneDepartureWarning 5 "SNA" 4 "RIGHT_WARNING_SEVERE" 3 "LEFT_WARNING_SEVERE" 2 "RIGHT_WARNING" 1 "LEFT_WARNING" 0 "NONE" ;
VAL_ 921 DAS_fleetSpeedState 3 "FLEETSPEED_HOLD" 2 "FLEETSPEED_ACTIVE" 1 "FLEETSPEED_AVAILABLE" 0 "FLEETSPEED_UNAVAILABLE" ;
VAL_ 921 DAS_autopilotHandsOnState 15 "LC_HANDS_ON_SNA" 8 "LC_HANDS_ON_SUSPENDED" 7 "LC_HANDS_ON_REQD_STRUCK_OUT" 5 "LC_HANDS_ON_REQD_CHIME_2" 4 "LC_HANDS_ON_REQD_CHIME_1" 3 "LC_HANDS_ON_REQD_VISUAL" 2 "LC_HANDS_ON_REQD_NOT_DETECTED" 1 "LC_HANDS_ON_REQD_DETECTED" 0 "LC_HANDS_ON_NOT_REQD" ;
VAL_ 921 DAS_autoLaneChangeState 31 "ALC_SNA" 30 "ALC_ABORT_MISSION_PLAN_INVALID" 29 "ALC_ABORT_TIMEOUT" 28 "ALC_WAITING_HANDS_ON" 27 "ALC_BLOCKED_LANE_TYPE_R" 26 "ALC_BLOCKED_LANE_TYPE_L" 25 "ALC_BLOCKED_VEH_TTC_AND_USS_R" 24 "ALC_BLOCKED_VEH_TTC_R" 23 "ALC_BLOCKED_VEH_TTC_AND_USS_L" 22 "ALC_BLOCKED_VEH_TTC_L" 21 "ALC_UNAVAILABLE_SOLID_LANE_LINE" 20 "ALC_ABORT_OTHER_REASON" 19 "ALC_ABORT_BLINKER_TURNED_OFF" 18 "ALC_ABORT_LC_HEALTH_BAD" 17 "ALC_ABORT_POOR_VIEW_RANGE" 16 "ALC_ABORT_SIDE_OBSTACLE_PRESENT_R" 15 "ALC_ABORT_SIDE_OBSTACLE_PRESENT_L" 14 "ALC_WAITING_FOR_FWD_OBST_TO_PASS_R" 13 "ALC_WAITING_FOR_FWD_OBST_TO_PASS_L" 12 "ALC_WAITING_FOR_SIDE_OBST_TO_PASS_R" 11 "ALC_WAITING_FOR_SIDE_OBST_TO_PASS_L" 10 "ALC_IN_PROGRESS_R" 9 "ALC_IN_PROGRESS_L" 8 "ALC_AVAILABLE_BOTH" 7 "ALC_AVAILABLE_ONLY_R" 6 "ALC_AVAILABLE_ONLY_L" 5 "ALC_UNAVAILABLE_VEHICLE_SPEED" 4 "ALC_UNAVAILABLE_EXITING_HIGHWAY" 3 "ALC_UNAVAILABLE_TP_FOLLOW" 2 "ALC_UNAVAILABLE_SONICS_INVALID" 1 "ALC_UNAVAILABLE_NO_LANES" 0 "ALC_UNAVAILABLE_DISABLED" ;
VAL_ 1001 DAS_headlightRequest 3 "DAS_HEADLIGHT_REQUEST_INVALID" 1 "DAS_HEADLIGHT_REQUEST_ON" 0 "DAS_HEADLIGHT_REQUEST_OFF" ;
VAL_ 1001 DAS_hazardLightRequest 3 "DAS_REQUEST_HAZARDS_SNA" 2 "DAS_REQUEST_HAZARDS_UNUSED" 1 "DAS_REQUEST_HAZARDS_ON" 0 "DAS_REQUEST_HAZARDS_OFF" ;
VAL_ 1001 DAS_wiperSpeed 15 "DAS_WIPER_SPEED_INVALID" 14 "DAS_WIPER_SPEED_14" 13 "DAS_WIPER_SPEED_13" 12 "DAS_WIPER_SPEED_12" 11 "DAS_WIPER_SPEED_11" 10 "DAS_WIPER_SPEED_10" 9 "DAS_WIPER_SPEED_9" 8 "DAS_WIPER_SPEED_8" 7 "DAS_WIPER_SPEED_7" 6 "DAS_WIPER_SPEED_6" 5 "DAS_WIPER_SPEED_5" 4 "DAS_WIPER_SPEED_4" 3 "DAS_WIPER_SPEED_3" 2 "DAS_WIPER_SPEED_2" 1 "DAS_WIPER_SPEED_1" 0 "DAS_WIPER_SPEED_OFF" ;
VAL_ 1001 DAS_turnIndicatorRequest 3 "DAS_TURN_INDICATOR_CANCEL" 2 "DAS_TURN_INDICATOR_RIGHT" 1 "DAS_TURN_INDICATOR_LEFT" 0 "DAS_TURN_INDICATOR_NONE" ;
VAL_ 1001 DAS_highLowBeamDecision 3 "DAS_HIGH_BEAM_SNA" 2 "DAS_HIGH_BEAM_ON" 1 "DAS_HIGH_BEAM_OFF" 0 "DAS_HIGH_BEAM_UNDECIDED" ;
VAL_ 1001 DAS_highLowBeamOffReason 5 "HIGH_BEAM_OFF_REASON_SNA" 4 "HIGH_BEAM_OFF_REASON_HEAD_LIGHT" 3 "HIGH_BEAM_OFF_REASON_AMBIENT_LIGHT" 2 "HIGH_BEAM_OFF_REASON_MOVING_RADAR_TARGET" 1 "HIGH_BEAM_OFF_REASON_MOVING_VISION_TARGET" 0 "HIGH_BEAM_ON" ;
VAL_ 1001 DAS_turnIndicatorRequestReason 6 "DAS_ACTIVE_COMMANDED_LANE_CHANGE" 5 "DAS_CANCEL_FORK" 4 "DAS_CANCEL_LANE_CHANGE" 3 "DAS_ACTIVE_FORK" 2 "DAS_ACTIVE_SPEED_LANE_CHANGE" 1 "DAS_ACTIVE_NAV_LANE_CHANGE" 0 "DAS_NONE" ;
VAL_ 1160 DAS_steeringAngleRequest 16384 "ZERO_ANGLE" ;
VAL_ 1160 DAS_steeringControlType 1 "ANGLE_CONTROL" 3 "DISABLED" 0 "NONE" 2 "RESERVED" ;
